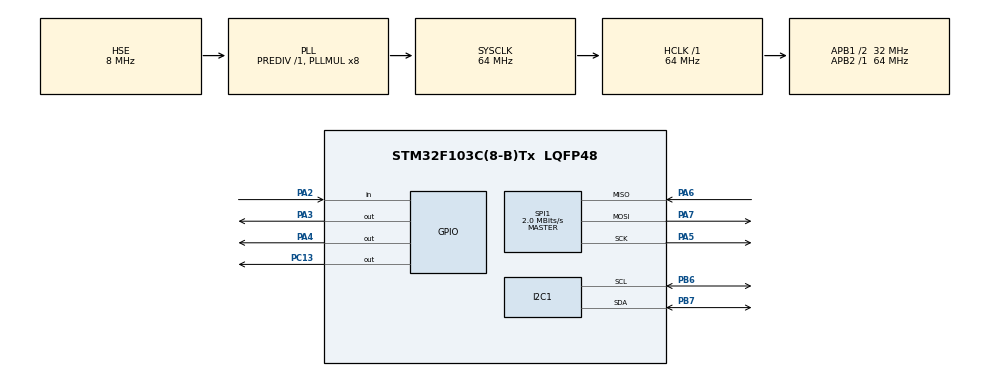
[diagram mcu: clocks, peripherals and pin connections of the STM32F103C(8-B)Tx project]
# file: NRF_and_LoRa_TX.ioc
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Mcu.Family=STM32F1
RCC.PLLSourceVirtual=RCC_PLLSOURCE_HSE
PA6.Mode=Full_Duplex_Master
PA7.Mode=Full_Duplex_Master
PD1-OSC_OUT.Mode=HSE-External-Oscillator
SPI1.VirtualType=VM_MASTER
PC13-TAMPER-RTC.Signal=GPIO_Output
PD0-OSC_IN.Signal=RCC_OSC_IN
RCC.APB1CLKDivider=RCC_HCLK_DIV2
PA3.GPIO_Speed=GPIO_SPEED_FREQ_HIGH
RCC.SYSCLKSource=RCC_SYSCLKSOURCE_PLLCLK
ProjectManager.StackSize=0x400
PD1-OSC_OUT.Signal=RCC_OSC_OUT
PA13.Signal=SYS_JTMS-SWDIO
PA4.PinState=GPIO_PIN_SET
ProjectManager.TargetToolchain=STM32CubeIDE
SPI1.Direction=SPI_DIRECTION_2LINES
RCC.HCLKFreq_Value=64000000
RCC.APB2TimFreq_Value=64000000
PB6.Signal=I2C1_SCL
PB6.Mode=I2C
SPI1.CalculateBaudRate=2.0 MBits/s
RCC.USBFreq_Value=64000000
RCC.AHBFreq_Value=64000000
PD0-OSC_IN.Mode=HSE-External-Oscillator
PA5.Signal=SPI1_SCK
board=custom
RCC.PLLMUL=RCC_PLL_MUL8
PA4.GPIO_Speed=GPIO_SPEED_FREQ_HIGH
RCC.APB2Freq_Value=64000000
SPI1.Mode=SPI_MODE_MASTER
PA14.Mode=Serial_Wire
PB7.Signal=I2C1_SDA
PA13.Mode=Serial_Wire
Mcu.Name=STM32F103C(8-B)Tx
PA2.Signal=GPIO_Input
PA4.Signal=GPIO_Output
RCC.SYSCLKFreq_VALUE=64000000
Mcu.Package=LQFP48
PA6.Signal=SPI1_MISO
PB7.Mode=I2C
PA14.Signal=SYS_JTCK-SWCLK
ProjectManager.HeapSize=0x200
NVIC.PriorityGroup=NVIC_PRIORITYGROUP_4
RCC.APB1TimFreq_Value=64000000
RCC.APB1Freq_Value=32000000
SPI1.BaudRatePrescaler=SPI_BAUDRATEPRESCALER_32
PA3.Signal=GPIO_Output
PA5.Mode=Full_Duplex_Master
PA7.Signal=SPI1_MOSI

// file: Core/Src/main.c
/* USER CODE BEGIN Header */
/**
  ******************************************************************************
  * @file           : main.c
  * @brief          : Main program body
  ******************************************************************************
  * @attention
  *
  * <h2><center>&copy; Copyright (c) 2021 STMicroelectronics.
  * All rights reserved.</center></h2>
  *
  * This software component is licensed by ST under BSD 3-Clause license,
  * the "License"; You may not use this file except in compliance with the
  * License. You may obtain a copy of the License at:
  *                        opensource.org/licenses/BSD-3-Clause
  *
  ******************************************************************************
  */
/* USER CODE END Header */
#include <OLED/fonts.h>
#include <OLED/oled_ssd1306.h>
#include <OLED/ssd1306.h>
#include "main.h"

I2C_HandleTypeDef hi2c1;

SPI_HandleTypeDef hspi1;

void SystemClock_Config(void);
static void MX_GPIO_Init(void);
static void MX_I2C1_Init(void);
static void MX_SPI1_Init(void);

int main(void)
{

  /* MCU Configuration--------------------------------------------------------*/

  /* Reset of all peripherals, Initializes the Flash interface and the Systick. */
  HAL_Init();

  /* Configure the system clock */
  SystemClock_Config();

  /* Initialize all configured peripherals */
  MX_GPIO_Init();
  MX_I2C1_Init();
  MX_SPI1_Init();

  /* Infinite loop */
  /* USER CODE BEGIN WHILE */

  ssd1306_Init();
  ssd1306_Fill(Black);
  ssd1306_UpdateScreen();

   // Test write on OLED
   ssd1306_SetCursor(0, 0);
   char test_main[20] = {0};
   strcpy(test_main, "NRF24L01 TX");
   ssd1306_WriteString(test_main,  Font_7x10, White);
   ssd1306_UpdateScreen();

  while (1)
  {
//	  HAL_GPIO_TogglePin(GPIOC, GPIO_PIN_13);
//	  HAL_Delay(300);

	  nrf_communication_test();
    /* USER CODE END WHILE */

  }
}

void SystemClock_Config(void)
{
  RCC_OscInitTypeDef RCC_OscInitStruct = {0};
  RCC_ClkInitTypeDef RCC_ClkInitStruct = {0};

  /** Initializes the RCC Oscillators according to the specified parameters
  * in the RCC_OscInitTypeDef structure.
  */
  RCC_OscInitStruct.OscillatorType = RCC_OSCILLATORTYPE_HSE;
  RCC_OscInitStruct.HSEState = RCC_HSE_ON;
  RCC_OscInitStruct.HSEPredivValue = RCC_HSE_PREDIV_DIV1;
  RCC_OscInitStruct.HSIState = RCC_HSI_ON;
  RCC_OscInitStruct.PLL.PLLState = RCC_PLL_ON;
  RCC_OscInitStruct.PLL.PLLSource = RCC_PLLSOURCE_HSE;
  RCC_OscInitStruct.PLL.PLLMUL = RCC_PLL_MUL8;
  if (HAL_RCC_OscConfig(&RCC_OscInitStruct) != HAL_OK)
  {
    Error_Handler();
  }
  /** Initializes the CPU, AHB and APB buses clocks
  */
  RCC_ClkInitStruct.ClockType = RCC_CLOCKTYPE_HCLK|RCC_CLOCKTYPE_SYSCLK
                              |RCC_CLOCKTYPE_PCLK1|RCC_CLOCKTYPE_PCLK2;
  RCC_ClkInitStruct.SYSCLKSource = RCC_SYSCLKSOURCE_PLLCLK;
  RCC_ClkInitStruct.AHBCLKDivider = RCC_SYSCLK_DIV1;
  RCC_ClkInitStruct.APB1CLKDivider = RCC_HCLK_DIV2;
  RCC_ClkInitStruct.APB2CLKDivider = RCC_HCLK_DIV1;

  if (HAL_RCC_ClockConfig(&RCC_ClkInitStruct, FLASH_LATENCY_2) != HAL_OK)
  {
    Error_Handler();
  }
}

static void MX_I2C1_Init(void)
{

  hi2c1.Instance = I2C1;
  hi2c1.Init.ClockSpeed = 100000;
  hi2c1.Init.DutyCycle = I2C_DUTYCYCLE_2;
  hi2c1.Init.OwnAddress1 = 0;
  hi2c1.Init.AddressingMode = I2C_ADDRESSINGMODE_7BIT;
  hi2c1.Init.DualAddressMode = I2C_DUALADDRESS_DISABLE;
  hi2c1.Init.OwnAddress2 = 0;
  hi2c1.Init.GeneralCallMode = I2C_GENERALCALL_DISABLE;
  hi2c1.Init.NoStretchMode = I2C_NOSTRETCH_DISABLE;
  if (HAL_I2C_Init(&hi2c1) != HAL_OK)
  {
    Error_Handler();
  }

}

static void MX_SPI1_Init(void)
{

  /* SPI1 parameter configuration*/
  hspi1.Instance = SPI1;
  hspi1.Init.Mode = SPI_MODE_MASTER;
  hspi1.Init.Direction = SPI_DIRECTION_2LINES;
  hspi1.Init.DataSize = SPI_DATASIZE_8BIT;
  hspi1.Init.CLKPolarity = SPI_POLARITY_LOW;
  hspi1.Init.CLKPhase = SPI_PHASE_1EDGE;
  hspi1.Init.NSS = SPI_NSS_SOFT;
  hspi1.Init.BaudRatePrescaler = SPI_BAUDRATEPRESCALER_16;
  hspi1.Init.FirstBit = SPI_FIRSTBIT_MSB;
  hspi1.Init.TIMode = SPI_TIMODE_DISABLE;
  hspi1.Init.CRCCalculation = SPI_CRCCALCULATION_DISABLE;
  hspi1.Init.CRCPolynomial = 10;
  if (HAL_SPI_Init(&hspi1) != HAL_OK)
  {
    Error_Handler();
  }

}

static void MX_GPIO_Init(void)
{
  GPIO_InitTypeDef GPIO_InitStruct = {0};

  /* GPIO Ports Clock Enable */
  __HAL_RCC_GPIOC_CLK_ENABLE();
  __HAL_RCC_GPIOD_CLK_ENABLE();
  __HAL_RCC_GPIOA_CLK_ENABLE();
  __HAL_RCC_GPIOB_CLK_ENABLE();

  /*Configure GPIO pin Output Level */
  HAL_GPIO_WritePin(GPIOC, GPIO_PIN_13, GPIO_PIN_RESET);

  /*Configure GPIO pin Output Level */
  HAL_GPIO_WritePin(GPIOA, GPIO_PIN_3, GPIO_PIN_RESET);

  /*Configure GPIO pin Output Level */
  HAL_GPIO_WritePin(GPIOA, GPIO_PIN_4, GPIO_PIN_SET);

  /*Configure GPIO pin : PC13 */
  GPIO_InitStruct.Pin = GPIO_PIN_13;
  GPIO_InitStruct.Mode = GPIO_MODE_OUTPUT_PP;
  GPIO_InitStruct.Pull = GPIO_NOPULL;
  GPIO_InitStruct.Speed = GPIO_SPEED_FREQ_LOW;
  HAL_GPIO_Init(GPIOC, &GPIO_InitStruct);

  /*Configure GPIO pin : PA2 */
  GPIO_InitStruct.Pin = GPIO_PIN_2;
  GPIO_InitStruct.Mode = GPIO_MODE_INPUT;
  GPIO_InitStruct.Pull = GPIO_NOPULL;
  HAL_GPIO_Init(GPIOA, &GPIO_InitStruct);

  /*Configure GPIO pins : PA3 PA4 */
  GPIO_InitStruct.Pin = GPIO_PIN_3|GPIO_PIN_4;
  GPIO_InitStruct.Mode = GPIO_MODE_OUTPUT_PP;
  GPIO_InitStruct.Pull = GPIO_NOPULL;
  GPIO_InitStruct.Speed = GPIO_SPEED_FREQ_HIGH;
  HAL_GPIO_Init(GPIOA, &GPIO_InitStruct);

}

void Error_Handler(void)
{
  __disable_irq();
  while (1)
  {
  }
}

/************************ (C) COPYRIGHT STMicroelectronics *****END OF FILE****/
